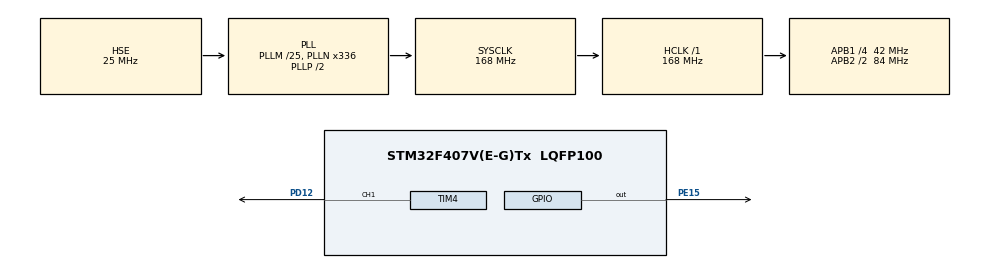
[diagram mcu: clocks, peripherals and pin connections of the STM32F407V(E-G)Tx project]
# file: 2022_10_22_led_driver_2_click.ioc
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Mcu.Family=STM32F4
Mcu.Name=STM32F407V(E-G)Tx
Mcu.Package=LQFP100
NVIC.PriorityGroup=NVIC_PRIORITYGROUP_4
PA13.Mode=Serial_Wire
PA13.Signal=SYS_JTMS-SWDIO
PA14.Mode=Serial_Wire
PA14.Signal=SYS_JTCK-SWCLK
PD12.GPIO_Speed=GPIO_SPEED_FREQ_VERY_HIGH
PD12.Signal=S_TIM4_CH1
PE15.Signal=GPIO_Output
PH0-OSC_IN.Mode=HSE-External-Oscillator
PH0-OSC_IN.Signal=RCC_OSC_IN
PH1-OSC_OUT.Mode=HSE-External-Oscillator
PH1-OSC_OUT.Signal=RCC_OSC_OUT
ProjectManager.HeapSize=0x200
ProjectManager.StackSize=0x400
ProjectManager.TargetToolchain=MDK-ARM V5.32
RCC.48MHZClocksFreq_Value=84000000
RCC.AHBFreq_Value=168000000
RCC.APB1CLKDivider=RCC_HCLK_DIV4
RCC.APB1Freq_Value=42000000
RCC.APB1TimFreq_Value=84000000
RCC.APB2CLKDivider=RCC_HCLK_DIV2
RCC.APB2Freq_Value=84000000
RCC.APB2TimFreq_Value=168000000
RCC.CortexFreq_Value=168000000
RCC.HCLKFreq_Value=168000000
RCC.HSE_VALUE=25000000
RCC.HSI_VALUE=16000000
RCC.LSE_VALUE=32768
RCC.PLLM=25
RCC.PLLN=336
RCC.PLLSourceVirtual=RCC_PLLSOURCE_HSE
RCC.SYSCLKFreq_VALUE=168000000
RCC.SYSCLKSource=RCC_SYSCLKSOURCE_PLLCLK
RCC.VCOOutputFreq_Value=336000000
SH.S_TIM4_CH1.0=TIM4_CH1,PWM Generation1 CH1
TIM4.Channel-PWM\ Generation1\ CH1=TIM_CHANNEL_1
TIM4.Period=400
TIM4.Prescaler=21
VP_TIM4_VS_ClockSourceINT.Mode=Internal
board=custom

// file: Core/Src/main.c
/* USER CODE BEGIN Header */
/**
  ******************************************************************************
  * @file           : main.c
  * @brief          : Main program body
  ******************************************************************************
  * @attention
  *
  * Copyright (c) 2022 STMicroelectronics.
  * All rights reserved.
  *
  * This software is licensed under terms that can be found in the LICENSE file
  * in the root directory of this software component.
  * If no LICENSE file comes with this software, it is provided AS-IS.
  *
  ******************************************************************************
  */
/* USER CODE END Header */
#include "main.h"

TIM_HandleTypeDef htim4;

void SystemClock_Config(void);
static void MX_GPIO_Init(void);
static void MX_TIM4_Init(void);

/* USER CODE BEGIN 0 */
uint16_t counter;
/* USER CODE END 0 */

int main(void)
{

  /* MCU Configuration--------------------------------------------------------*/

  /* Reset of all peripherals, Initializes the Flash interface and the Systick. */
  HAL_Init();

  /* Configure the system clock */
  SystemClock_Config();

  /* Initialize all configured peripherals */
  MX_GPIO_Init();
  MX_TIM4_Init();
  /* USER CODE BEGIN 2 */
	HAL_TIM_PWM_Start(&htim4,TIM_CHANNEL_1);
  /* USER CODE END 2 */

  /* Infinite loop */
  /* USER CODE BEGIN WHILE */
  while (1)
  {
		counter+=5;
		HAL_GPIO_TogglePin(GPIOE,GPIO_PIN_15);
		TIM4->CCR1=counter;
		HAL_Delay(300);
		if(counter>400)
			counter = 0;
    /* USER CODE END WHILE */

  }
}

void SystemClock_Config(void)
{
  RCC_OscInitTypeDef RCC_OscInitStruct = {0};
  RCC_ClkInitTypeDef RCC_ClkInitStruct = {0};

  /** Configure the main internal regulator output voltage
  */
  __HAL_RCC_PWR_CLK_ENABLE();
  __HAL_PWR_VOLTAGESCALING_CONFIG(PWR_REGULATOR_VOLTAGE_SCALE1);

  /** Initializes the RCC Oscillators according to the specified parameters
  * in the RCC_OscInitTypeDef structure.
  */
  RCC_OscInitStruct.OscillatorType = RCC_OSCILLATORTYPE_HSE;
  RCC_OscInitStruct.HSEState = RCC_HSE_ON;
  RCC_OscInitStruct.PLL.PLLState = RCC_PLL_ON;
  RCC_OscInitStruct.PLL.PLLSource = RCC_PLLSOURCE_HSE;
  RCC_OscInitStruct.PLL.PLLM = 25;
  RCC_OscInitStruct.PLL.PLLN = 336;
  RCC_OscInitStruct.PLL.PLLP = RCC_PLLP_DIV2;
  RCC_OscInitStruct.PLL.PLLQ = 4;
  if (HAL_RCC_OscConfig(&RCC_OscInitStruct) != HAL_OK)
  {
    Error_Handler();
  }

  /** Initializes the CPU, AHB and APB buses clocks
  */
  RCC_ClkInitStruct.ClockType = RCC_CLOCKTYPE_HCLK|RCC_CLOCKTYPE_SYSCLK
                              |RCC_CLOCKTYPE_PCLK1|RCC_CLOCKTYPE_PCLK2;
  RCC_ClkInitStruct.SYSCLKSource = RCC_SYSCLKSOURCE_PLLCLK;
  RCC_ClkInitStruct.AHBCLKDivider = RCC_SYSCLK_DIV1;
  RCC_ClkInitStruct.APB1CLKDivider = RCC_HCLK_DIV4;
  RCC_ClkInitStruct.APB2CLKDivider = RCC_HCLK_DIV2;

  if (HAL_RCC_ClockConfig(&RCC_ClkInitStruct, FLASH_LATENCY_5) != HAL_OK)
  {
    Error_Handler();
  }
}

static void MX_TIM4_Init(void)
{

  TIM_ClockConfigTypeDef sClockSourceConfig = {0};
  TIM_MasterConfigTypeDef sMasterConfig = {0};
  TIM_OC_InitTypeDef sConfigOC = {0};

  htim4.Instance = TIM4;
  htim4.Init.Prescaler = 21;
  htim4.Init.CounterMode = TIM_COUNTERMODE_UP;
  htim4.Init.Period = 400;
  htim4.Init.ClockDivision = TIM_CLOCKDIVISION_DIV1;
  htim4.Init.AutoReloadPreload = TIM_AUTORELOAD_PRELOAD_DISABLE;
  if (HAL_TIM_Base_Init(&htim4) != HAL_OK)
  {
    Error_Handler();
  }
  sClockSourceConfig.ClockSource = TIM_CLOCKSOURCE_INTERNAL;
  if (HAL_TIM_ConfigClockSource(&htim4, &sClockSourceConfig) != HAL_OK)
  {
    Error_Handler();
  }
  if (HAL_TIM_PWM_Init(&htim4) != HAL_OK)
  {
    Error_Handler();
  }
  sMasterConfig.MasterOutputTrigger = TIM_TRGO_RESET;
  sMasterConfig.MasterSlaveMode = TIM_MASTERSLAVEMODE_DISABLE;
  if (HAL_TIMEx_MasterConfigSynchronization(&htim4, &sMasterConfig) != HAL_OK)
  {
    Error_Handler();
  }
  sConfigOC.OCMode = TIM_OCMODE_PWM1;
  sConfigOC.Pulse = 0;
  sConfigOC.OCPolarity = TIM_OCPOLARITY_HIGH;
  sConfigOC.OCFastMode = TIM_OCFAST_DISABLE;
  if (HAL_TIM_PWM_ConfigChannel(&htim4, &sConfigOC, TIM_CHANNEL_1) != HAL_OK)
  {
    Error_Handler();
  }
  HAL_TIM_MspPostInit(&htim4);

}

static void MX_GPIO_Init(void)
{
  GPIO_InitTypeDef GPIO_InitStruct = {0};

  /* GPIO Ports Clock Enable */
  __HAL_RCC_GPIOH_CLK_ENABLE();
  __HAL_RCC_GPIOE_CLK_ENABLE();
  __HAL_RCC_GPIOD_CLK_ENABLE();
  __HAL_RCC_GPIOA_CLK_ENABLE();

  /*Configure GPIO pin Output Level */
  HAL_GPIO_WritePin(GPIOE, GPIO_PIN_15, GPIO_PIN_RESET);

  /*Configure GPIO pin : PE15 */
  GPIO_InitStruct.Pin = GPIO_PIN_15;
  GPIO_InitStruct.Mode = GPIO_MODE_OUTPUT_PP;
  GPIO_InitStruct.Pull = GPIO_NOPULL;
  GPIO_InitStruct.Speed = GPIO_SPEED_FREQ_LOW;
  HAL_GPIO_Init(GPIOE, &GPIO_InitStruct);

}

void Error_Handler(void)
{
  __disable_irq();
  while (1)
  {
  }
}
